# BL808 register map
File version: 0.1
Registers are access not given, no defined reset value unless marked. A register's access mark holds for its fields unless they carry their own. Offsets are from the block's base; [hi:lo] are bit positions.

## PDS
Base 0x2000E000
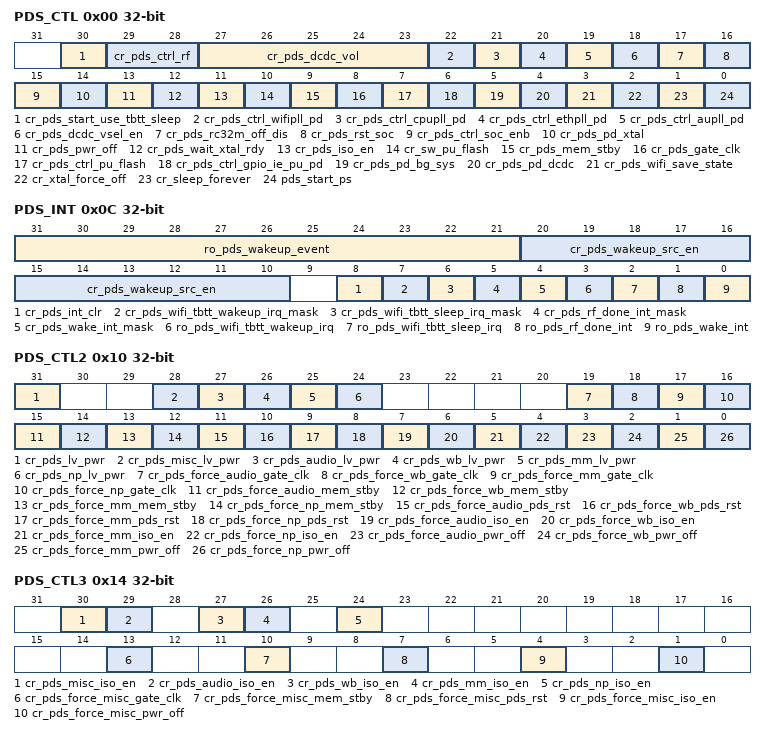
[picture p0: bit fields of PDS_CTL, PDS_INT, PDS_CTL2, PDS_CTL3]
0x00 PDS_CTL
  [30] cr_pds_start_use_tbtt_sleep rw, [29:28] cr_pds_ctrl_rf rw, [27:23] cr_pds_dcdc_vol rw, [22] cr_pds_ctrl_wifipll_pd rw, [21] cr_pds_ctrl_cpupll_pd rw, [20] cr_pds_ctrl_ethpll_pd rw, [19] cr_pds_ctrl_aupll_pd rw, [18] cr_pds_dcdc_vsel_en rw, [17] cr_pds_rc32m_off_dis rw, [16] cr_pds_rst_soc rw, [15] cr_pds_ctrl_soc_enb rw, [14] cr_pds_pd_xtal rw, [13] cr_pds_pwr_off rw, [12] cr_pds_wait_xtal_rdy rw, [11] cr_pds_iso_en rw, [10] cr_sw_pu_flash rw, [9] cr_pds_mem_stby rw, [8] cr_pds_gate_clk rw, [7] cr_pds_ctrl_pu_flash rw, [6] cr_pds_ctrl_gpio_ie_pu_pd rw, [5] cr_pds_pd_bg_sys rw, [4] cr_pds_pd_dcdc rw, [3] cr_pds_wifi_save_state rw, [2] cr_xtal_force_off rw, [1] cr_sleep_forever rw, [0] pds_start_ps write-once
0x04 PDS_TIME1 rw
  [31:0] cr_sleep_duration
0x0C PDS_INT
  [31:21] ro_pds_wakeup_event ro, [20:10] cr_pds_wakeup_src_en rw, [8] cr_pds_int_clr rw, [7] cr_pds_wifi_tbtt_wakeup_irq_mask rw, [6] cr_pds_wifi_tbtt_sleep_irq_mask rw, [5] cr_pds_rf_done_int_mask rw, [4] cr_pds_wake_int_mask rw, [3] ro_pds_wifi_tbtt_wakeup_irq ro, [2] ro_pds_wifi_tbtt_sleep_irq ro, [1] ro_pds_rf_done_int ro, [0] ro_pds_wake_int ro
0x10 PDS_CTL2
  [31] cr_pds_lv_pwr rw, [28] cr_pds_misc_lv_pwr rw, [27] cr_pds_audio_lv_pwr rw, [26] cr_pds_wb_lv_pwr rw, [25] cr_pds_mm_lv_pwr rw, [24] cr_pds_np_lv_pwr rw, [19] cr_pds_force_audio_gate_clk rw, [18] cr_pds_force_wb_gate_clk rw, [17] cr_pds_force_mm_gate_clk rw, [16] cr_pds_force_np_gate_clk rw, [15] cr_pds_force_audio_mem_stby rw, [14] cr_pds_force_wb_mem_stby rw, [13] cr_pds_force_mm_mem_stby rw, [12] cr_pds_force_np_mem_stby rw, [11] cr_pds_force_audio_pds_rst rw, [10] cr_pds_force_wb_pds_rst rw, [9] cr_pds_force_mm_pds_rst rw, [8] cr_pds_force_np_pds_rst rw, [7] cr_pds_force_audio_iso_en rw, [6] cr_pds_force_wb_iso_en rw, [5] cr_pds_force_mm_iso_en rw, [4] cr_pds_force_np_iso_en rw, [3] cr_pds_force_audio_pwr_off rw, [2] cr_pds_force_wb_pwr_off rw, [1] cr_pds_force_mm_pwr_off rw, [0] cr_pds_force_np_pwr_off rw
0x14 PDS_CTL3
  [30] cr_pds_misc_iso_en rw, [29] cr_pds_audio_iso_en rw, [27] cr_pds_wb_iso_en rw, [26] cr_pds_mm_iso_en rw, [24] cr_pds_np_iso_en rw, [13] cr_pds_force_misc_gate_clk rw, [10] cr_pds_force_misc_mem_stby rw, [7] cr_pds_force_misc_pds_rst rw, [4] cr_pds_force_misc_iso_en rw, [1] cr_pds_force_misc_pwr_off rw
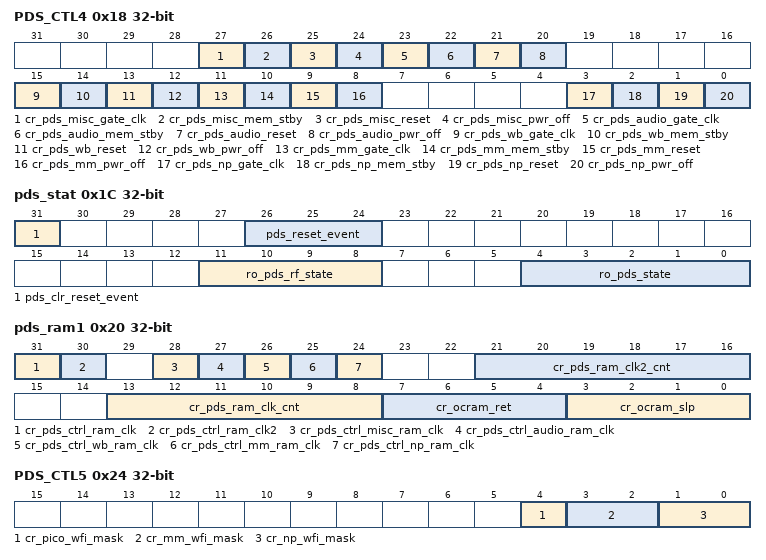
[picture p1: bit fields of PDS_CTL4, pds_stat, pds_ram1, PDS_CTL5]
0x18 PDS_CTL4
  [27] cr_pds_misc_gate_clk rw, [26] cr_pds_misc_mem_stby rw, [25] cr_pds_misc_reset rw, [24] cr_pds_misc_pwr_off rw, [23] cr_pds_audio_gate_clk rw, [22] cr_pds_audio_mem_stby rw, [21] cr_pds_audio_reset rw, [20] cr_pds_audio_pwr_off rw, [15] cr_pds_wb_gate_clk rw, [14] cr_pds_wb_mem_stby rw, [13] cr_pds_wb_reset rw, [12] cr_pds_wb_pwr_off rw, [11] cr_pds_mm_gate_clk rw, [10] cr_pds_mm_mem_stby rw, [9] cr_pds_mm_reset rw, [8] cr_pds_mm_pwr_off rw, [3] cr_pds_np_gate_clk rw, [2] cr_pds_np_mem_stby rw, [1] cr_pds_np_reset rw, [0] cr_pds_np_pwr_off rw
0x1C pds_stat
  [31] pds_clr_reset_event write-once, [26:24] pds_reset_event ro, [11:8] ro_pds_rf_state ro, [4:0] ro_pds_state ro
0x20 pds_ram1
  [31] cr_pds_ctrl_ram_clk rw, [30] cr_pds_ctrl_ram_clk2 rw, [28] cr_pds_ctrl_misc_ram_clk rw, [27] cr_pds_ctrl_audio_ram_clk rw, [26] cr_pds_ctrl_wb_ram_clk rw, [25] cr_pds_ctrl_mm_ram_clk rw, [24] cr_pds_ctrl_np_ram_clk rw, [21:16] cr_pds_ram_clk2_cnt rw, [13:8] cr_pds_ram_clk_cnt rw, [7:4] cr_ocram_ret rw, [3:0] cr_ocram_slp rw
0x24 PDS_CTL5
  [4] cr_pico_wfi_mask rw, [3:2] cr_mm_wfi_mask rw, [1:0] cr_np_wfi_mask rw
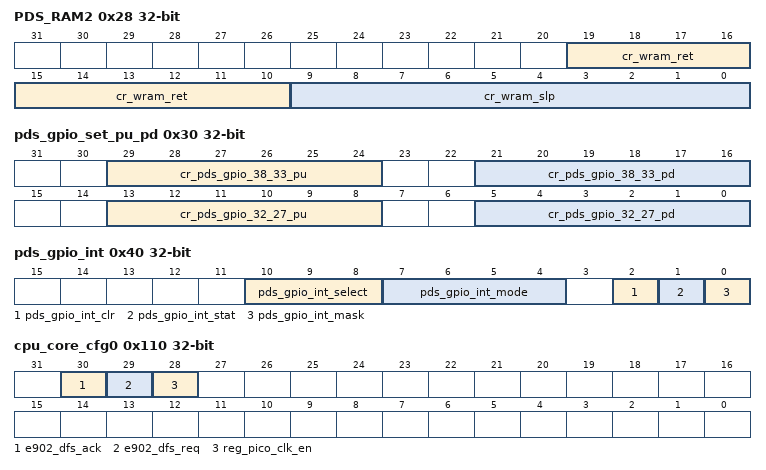
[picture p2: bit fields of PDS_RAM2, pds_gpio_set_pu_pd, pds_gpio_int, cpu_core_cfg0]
0x28 PDS_RAM2
  [19:10] cr_wram_ret rw, [9:0] cr_wram_slp rw
0x30 pds_gpio_set_pu_pd
  [29:24] cr_pds_gpio_38_33_pu rw, [21:16] cr_pds_gpio_38_33_pd rw, [13:8] cr_pds_gpio_32_27_pu rw, [5:0] cr_pds_gpio_32_27_pd rw
0x40 pds_gpio_int
  [10:8] pds_gpio_int_select rw, [7:4] pds_gpio_int_mode rw, [2] pds_gpio_int_clr rw, [1] pds_gpio_int_stat ro, [0] pds_gpio_int_mask rw
0x100 l1c_range_h
  [30:10] l1c_range_h rw
0x104 l1c_range_l
  [30:10] l1c_range_l rw
0x110 cpu_core_cfg0
  [30] e902_dfs_ack ro, [29] e902_dfs_req rw, [28] reg_pico_clk_en rw
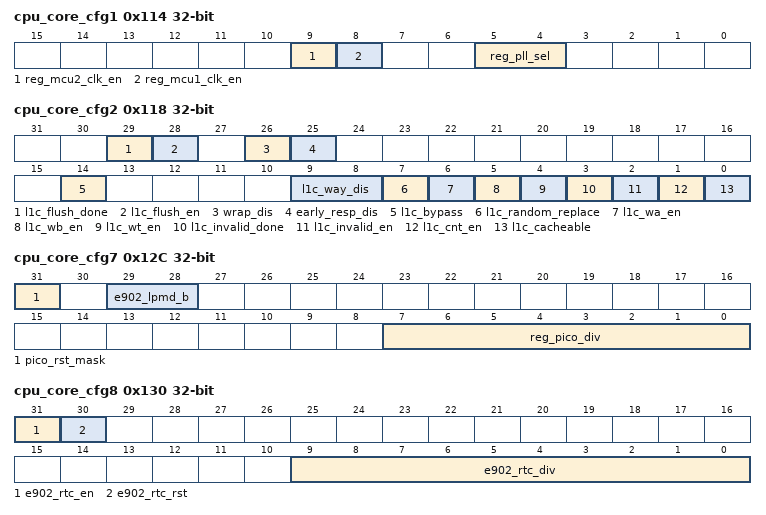
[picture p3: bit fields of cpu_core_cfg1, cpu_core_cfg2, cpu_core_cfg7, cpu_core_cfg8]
0x114 cpu_core_cfg1
  [9] reg_mcu2_clk_en rw, [8] reg_mcu1_clk_en rw, [5:4] reg_pll_sel rw
0x118 cpu_core_cfg2
  [29] l1c_flush_done ro, [28] l1c_flush_en rw, [26] wrap_dis rw, [25] early_resp_dis rw, [14] l1c_bypass rw, [9:8] l1c_way_dis rw, [7] l1c_random_replace rw, [6] l1c_wa_en rw, [5] l1c_wb_en rw, [4] l1c_wt_en rw, [3] l1c_invalid_done ro, [2] l1c_invalid_en rw, [1] l1c_cnt_en rw, [0] l1c_cacheable rw
0x11C cpu_core_cfg3 ro
  [31:0] pico_hit_cnt_lsb
0x120 cpu_core_cfg4 ro
  [31:0] pico_hit_cnt_msb
0x124 cpu_core_cfg5 ro
  [31:0] pico_miss_cnt
0x128 cpu_core_cfg6
  [30:28] l1c_fsm ro
0x12C cpu_core_cfg7
  [31] pico_rst_mask rw, [29:28] e902_lpmd_b ro, [7:0] reg_pico_div rw
0x130 cpu_core_cfg8
  [31] e902_rtc_en rw, [30] e902_rtc_rst rw, [9:0] e902_rtc_div rw
0x134 cpu_core_cfg9 ro
  [31:0] pico_rtc_cnt_l
0x138 cpu_core_cfg10 ro
  [31:0] pico_rtc_cnt_h
0x13C cpu_core_cfg11 ro
  [31:0] pico_rom_misr_dataout
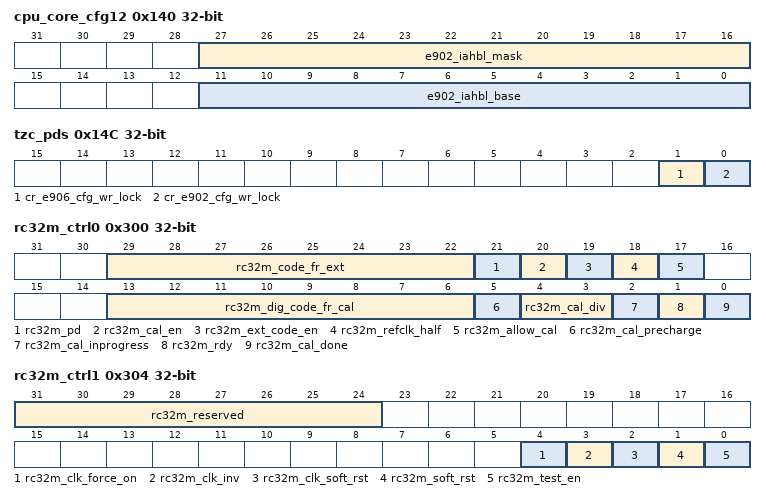
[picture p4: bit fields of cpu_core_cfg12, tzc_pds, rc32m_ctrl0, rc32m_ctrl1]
0x140 cpu_core_cfg12
  [27:16] e902_iahbl_mask rw, [11:0] e902_iahbl_base rw
0x144 cpu_core_cfg13 rw
  [31:0] e902_rst_addr
0x148 cpu_core_cfg14 rw
  [31:0] e906_rst_addr
0x14C tzc_pds
  [1] cr_e906_cfg_wr_lock rw, [0] cr_e902_cfg_wr_lock rw
0x300 rc32m_ctrl0
  [29:22] rc32m_code_fr_ext rw, [21] rc32m_pd rw, [20] rc32m_cal_en rw, [19] rc32m_ext_code_en rw, [18] rc32m_refclk_half rw, [17] rc32m_allow_cal rw, [13:6] rc32m_dig_code_fr_cal ro, [5] rc32m_cal_precharge ro, [4:3] rc32m_cal_div rw, [2] rc32m_cal_inprogress ro, [1] rc32m_rdy ro, [0] rc32m_cal_done ro
0x304 rc32m_ctrl1
  [31:24] rc32m_reserved rw, [4] rc32m_clk_force_on rw, [3] rc32m_clk_inv rw, [2] rc32m_clk_soft_rst rw, [1] rc32m_soft_rst rw, [0] rc32m_test_en rw
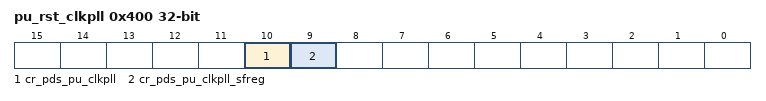
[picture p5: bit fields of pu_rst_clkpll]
0x400 pu_rst_clkpll
  [10] cr_pds_pu_clkpll rw, [9] cr_pds_pu_clkpll_sfreg rw
